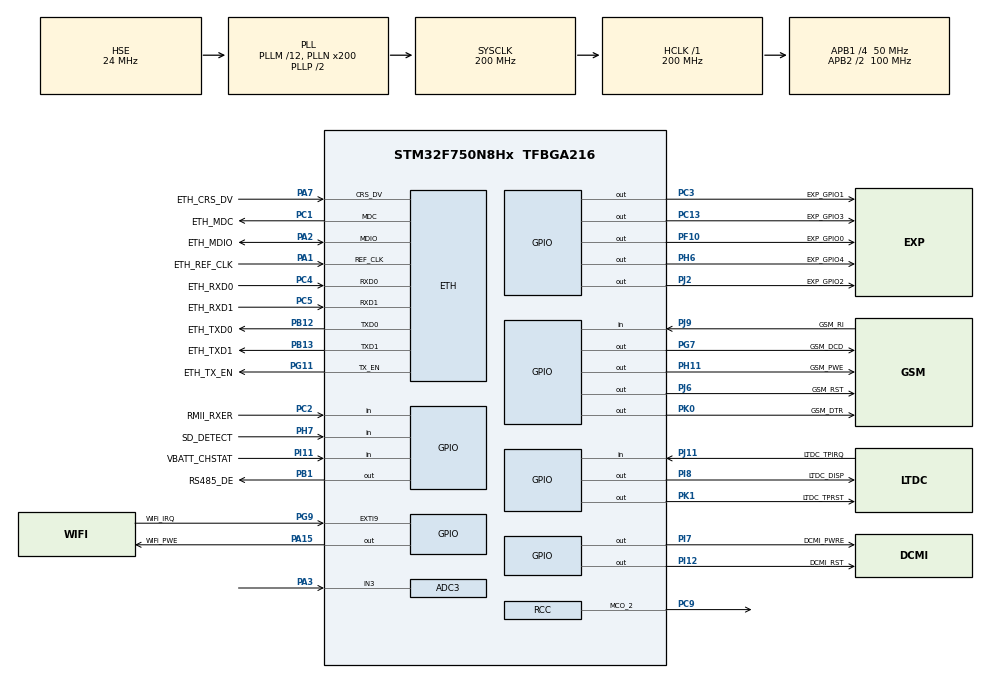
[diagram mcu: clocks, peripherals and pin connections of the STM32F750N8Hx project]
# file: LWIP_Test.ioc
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ADC1.Channel-2\#ChannelRegularConversion=ADC_CHANNEL_3
ADC1.ClockPrescaler=ADC_CLOCK_SYNC_PCLK_DIV6
ADC1.NbrOfConversionFlag=1
ADC1.Rank-2\#ChannelRegularConversion=1
ADC1.SamplingTime-2\#ChannelRegularConversion=ADC_SAMPLETIME_3CYCLES
ADC1.master=1
ADC3.Channel-0\#ChannelRegularConversion=ADC_CHANNEL_3
ADC3.ClockPrescaler=ADC_CLOCK_SYNC_PCLK_DIV6
ADC3.InjNumberOfConversion=0
ADC3.NbrOfConversion=1
ADC3.NbrOfConversionFlag=1
ADC3.Rank-0\#ChannelRegularConversion=1
ADC3.SamplingTime-0\#ChannelRegularConversion=ADC_SAMPLETIME_3CYCLES
ETH.MediaInterface=ETH_MEDIA_INTERFACE_RMII
ETH.PhyAddress=0
FREERTOS.Tasks01=defaultTask,0,128,StartDefaultTask,Default,NULL
LWIP.GATEWAY_ADDRESS=192.168.001.001
LWIP.IP_ADDRESS=192.168.001.050
LWIP.LWIP_DHCP=0
LWIP.NETMASK_ADDRESS=255.255.255.000
LWIP.Version=v2.0.3_Cube
Mcu.Family=STM32F7
Mcu.Name=STM32F750N8Hx
Mcu.Package=TFBGA216
NVIC.ETH_IRQn=true\:5\:0\:false\:false\:true\:true\:false\:true
NVIC.PriorityGroup=NVIC_PRIORITYGROUP_4
NVIC.RCC_IRQn=true\:5\:0\:false\:false\:true\:true\:true\:false
NVIC.TIM1_UP_TIM10_IRQn=true\:0\:0\:false\:false\:true\:false\:false\:true
NVIC.TimeBase=TIM1_UP_TIM10_IRQn
NVIC.TimeBaseIP=TIM1
PA0/WKUP.GPIO_Label=SYS_WAKUP
PA0/WKUP.Mode=SYS_WakeUp0
PA0/WKUP.Signal=SYS_WKUP1
PA1.GPIO_Label=ETH_REF_CLK
PA1.Mode=RMII
PA1.Signal=ETH_REF_CLK
PA10.GPIO_Label=WiFi_RX
PA10.Signal=USART1_RX
PA11.GPIO_Label=WiFi_CTS
PA11.Signal=USART1_CTS
PA12.GPIO_Label=WiFi_RTS
PA12.Signal=USART1_RTS
PA13.GPIO_Label=SWDIO
PA13.Mode=Trace_Asynchronous_SW
PA13.Signal=SYS_JTMS-SWDIO
PA14.GPIO_Label=SWCLK
PA14.Mode=Trace_Asynchronous_SW
PA14.Signal=SYS_JTCK-SWCLK
PA15.GPIO_Label=WiFi_PWE
PA15.Signal=GPIO_Output
PA2.GPIO_Label=ETH_MDIO
PA2.Mode=RMII
PA2.Signal=ETH_MDIO
PA3.Signal=ADCx_IN3
PA4.GPIO_Label=DCMI_HSYNC
PA4.GPIO_Speed=GPIO_SPEED_FREQ_VERY_HIGH
PA4.Signal=DCMI_HSYNC
PA5.GPIO_Label=DCMI_SCL
PA5.Signal=SPI1_SCK
PA6.GPIO_Label=DCMI_PIXCLK
PA6.GPIO_Speed=GPIO_SPEED_FREQ_VERY_HIGH
PA6.Signal=DCMI_PIXCLK
PA7.GPIO_Label=ETH_CRS_DV
PA7.Mode=RMII
PA7.Signal=ETH_CRS_DV
PA8.Signal=I2C3_SCL
PA9.GPIO_Label=WiFi_TX
PA9.Signal=USART1_TX
PB0.GPIO_Label=DCMI_LIGHT
PB0.Signal=TIM8_CH2N
PB1.GPIO_Label=RS485_DE
PB1.Signal=GPIO_Output
PB10.GPIO_Label=RS485_TX
PB10.Signal=USART3_TX
PB11.GPIO_Label=RS485_RX
PB11.Signal=USART3_RX
PB12.GPIO_Label=ETH_TXD0
PB12.Mode=RMII
PB12.Signal=ETH_TXD0
PB13.GPIO_Label=ETH_TXD1
PB13.Mode=RMII
PB13.Signal=ETH_TXD1
PB14.GPIO_Label=USB_DM
PB14.Signal=USB_OTG_HS_DM
PB15.GPIO_Label=USB_DP
PB15.Signal=USB_OTG_HS_DP
PB2.GPIO_Label=QSP_CLK
PB2.Signal=QUADSPI_CLK
PB3.GPIO_Label=SWO
PB3.Mode=Trace_Asynchronous_SW
PB3.Signal=SYS_JTDO-SWO
PB4.GPIO_Label=DCMI_MISO
PB4.Signal=SPI1_MISO
PB5.GPIO_Label=DCMI_MOSI
PB5.Signal=SPI1_MOSI
PB6.GPIO_Label=QSP_NCS
PB6.Signal=QUADSPI_BK1_NCS
PB7.GPIO_Label=DCMI_SDA
PB7.Signal=I2C1_SDA
PB8.GPIO_Label=DCMI_SCL
PB8.Signal=I2C1_SCL
PB9.GPIO_Label=CAN_TX
PB9.Signal=CAN1_TX
PC0.GPIO_Label=FMC_SDNWE
PC0.Signal=FMC_SDNWE
PC1.GPIO_Label=ETH_MDC
PC1.Mode=RMII
PC1.Signal=ETH_MDC
PC10.GPIO_Label=SD_D2
PC10.Signal=SDMMC1_D2
PC11.GPIO_Label=SD_D3
PC11.Signal=SDMMC1_D3
PC12.GPIO_Label=SD_CK
PC12.Signal=SDMMC1_CK
PC13.GPIO_Label=EXP_GPIO3
PC13.Signal=GPIO_Output
PC14/OSC32_IN.GPIO_Label=LS_OSC1
PC14/OSC32_IN.Mode=LSE-External-Oscillator
PC14/OSC32_IN.Signal=RCC_OSC32_IN
PC15/OSC32_OUT.GPIO_Label=LS_OSC2
PC15/OSC32_OUT.Mode=LSE-External-Oscillator
PC15/OSC32_OUT.Signal=RCC_OSC32_OUT
PC2.GPIO_Label=RMII_RXER
PC2.Signal=GPIO_Input
PC3.GPIO_Label=EXP_GPIO1
PC3.Signal=GPIO_Output
PC4.GPIO_Label=ETH_RXD0
PC4.Mode=RMII
PC4.Signal=ETH_RXD0
PC5.GPIO_Label=ETH_RXD1
PC5.Mode=RMII
PC5.Signal=ETH_RXD1
PC6.GPIO_Label=DCMI_D0
PC6.GPIO_Speed=GPIO_SPEED_FREQ_VERY_HIGH
PC6.Signal=DCMI_D0
PC7.GPIO_Label=GSM_RX
PC7.Signal=USART6_RX
PC8.GPIO_Label=SD_D0
PC8.Signal=SDMMC1_D0
PC9.Mode=Clock-out-2
PC9.Signal=RCC_MCO_2
PD0.GPIO_Label=FMC_D2
PD0.Signal=FMC_D2_DA2
PD1.GPIO_Label=FMC_D3
PD1.Signal=FMC_D3_DA3
PD10.GPIO_Label=FMC_D15
PD10.Signal=FMC_D15_DA15
PD11.GPIO_Label=FMC_A16
PD11.Signal=FMC_A16_CLE
PD12.GPIO_Label=FMC_A17
PD12.Signal=FMC_A17_ALE
PD13.GPIO_Label=FMC_A18
PD13.Signal=FMC_A18
PD14.GPIO_Label=FMC_D0
PD14.Signal=FMC_D0_DA0
PD15.GPIO_Label=FMC_D1
PD15.Signal=FMC_D1_DA1
PD2.GPIO_Label=SD_CMD
PD2.Signal=SDMMC1_CMD
PD3.GPIO_Label=WiFi_SCK
PD3.Signal=SPI2_SCK
PD4.GPIO_Label=FMC_NOE
PD4.Signal=FMC_NOE
PD5.GPIO_Label=FMC_NWE
PD5.Signal=FMC_NWE
PD6.GPIO_Label=FMC_NWAIT
PD6.Signal=FMC_NWAIT
PD7.GPIO_Label=FMC_NE
PD7.Signal=FMC_NE1
PD8.GPIO_Label=FMC_D13
PD8.Signal=FMC_D13_DA13
PD9.GPIO_Label=FMC_D14
PD9.Signal=FMC_D14_DA14
PE0.GPIO_Label=FMC_NBL0
PE0.Signal=FMC_NBL0
PE1.GPIO_Label=FMC_NBL1
PE1.Signal=FMC_NBL1
PE10.GPIO_Label=FMC_D7
PE10.Signal=FMC_D7_DA7
PE11.GPIO_Label=FMC_D8
PE11.Signal=FMC_D8_DA8
PE12.GPIO_Label=FMC_D9
PE12.Signal=FMC_D9_DA9
PE13.GPIO_Label=FMC_D10
PE13.Signal=FMC_D10_DA10
PE14.GPIO_Label=FMC_D11
PE14.Signal=FMC_D11_DA11
PE15.GPIO_Label=FMC_D12
PE15.Signal=FMC_D12_DA12
PE2.GPIO_Label=QSP_IO2
PE2.Signal=QUADSPI_BK1_IO2
PE3.GPIO_Label=FMC_A19
PE3.Signal=FMC_A19
PE4.GPIO_Label=FMC_A20
PE4.Signal=FMC_A20
PE5.GPIO_Label=FMC_A21
PE5.Signal=FMC_A21
PE6.GPIO_Label=DCMI_D7
PE6.GPIO_Speed=GPIO_SPEED_FREQ_VERY_HIGH
PE6.Signal=DCMI_D7
PE7.GPIO_Label=FMC_D4
PE7.Signal=FMC_D4_DA4
PE8.GPIO_Label=FMC_D5
PE8.Signal=FMC_D5_DA5
PE9.GPIO_Label=FMC_D6
PE9.Signal=FMC_D6_DA6
PF0.GPIO_Label=FMC_A0
PF0.Signal=FMC_A0
PF1.GPIO_Label=FMC_A1
PF1.Signal=FMC_A1
PF10.GPIO_Label=EXP_GPIO0
PF10.Signal=GPIO_Output
PF11.GPIO_Label=FMC_SDNRAS
PF11.Signal=FMC_SDNRAS
PF12.GPIO_Label=FMC_A6
PF12.Signal=FMC_A6
PF13.GPIO_Label=FMC_A7
PF13.Signal=FMC_A7
PF14.GPIO_Label=FMC_A8
PF14.Signal=FMC_A8
PF15.GPIO_Label=FMC_A9
PF15.Signal=FMC_A9
PF2.GPIO_Label=FMC_A2
PF2.Signal=FMC_A2
PF3.GPIO_Label=FMC_A3
PF3.Signal=FMC_A3
PF4.GPIO_Label=FMC_A4
PF4.Signal=FMC_A4
PF5.GPIO_Label=FMC_A5
PF5.Signal=FMC_A5
PF6.GPIO_Label=QSP_IO3
PF6.Signal=QUADSPI_BK1_IO3
PF7.GPIO_Label=LTDC_BL
PF7.Signal=S_TIM11_CH1
PF8.GPIO_Label=QSP_IO0
PF8.Signal=QUADSPI_BK1_IO0
PF9.GPIO_Label=QSP_IO1
PF9.Signal=QUADSPI_BK1_IO1
PG0.GPIO_Label=FMC_A10
PG0.Signal=FMC_A10
PG1.GPIO_Label=FMC_A11
PG1.Signal=FMC_A11
PG10.GPIO_Label=DCMI_D2
PG10.GPIO_Speed=GPIO_SPEED_FREQ_VERY_HIGH
PG10.Signal=DCMI_D2
PG11.GPIO_Label=ETH_TX_EN
PG11.Mode=RMII
PG11.Signal=ETH_TX_EN
PG12.GPIO_Label=GSM_RTS
PG12.Signal=USART6_RTS
PG13.GPIO_Label=GSM_CTS
PG13.Signal=USART6_CTS
PG14.GPIO_Label=GSM_TX
PG14.Signal=USART6_TX
PG15.GPIO_Label=FMC_SDNCAS
PG15.Signal=FMC_SDNCAS
PG2.GPIO_Label=FMC_A12
PG2.Signal=FMC_A12
PG3.GPIO_Label=FMC_A13
PG3.Signal=FMC_A13
PG4.GPIO_Label=FMC_A14
PG4.Signal=FMC_A14_BA0
PG5.GPIO_Label=FMC_A15
PG5.Signal=FMC_A15_BA1
PG6.GPIO_Label=LTDC_R7
PG6.GPIO_Speed=GPIO_SPEED_FREQ_VERY_HIGH
PG6.Signal=LTDC_R7
PG7.GPIO_Label=GSM_DCD
PG7.Signal=GPIO_Output
PG8.GPIO_Label=FMC_SDCLK
PG8.Signal=FMC_SDCLK
PG9.GPIO_Label=WiFi_IRQ
PG9.Signal=GPXTI9
PH0/OSC_IN.GPIO_Label=HS_OSC1
PH0/OSC_IN.Mode=HSE-External-Oscillator
PH0/OSC_IN.Signal=RCC_OSC_IN
PH1/OSC_OUT.GPIO_Label=HS_OSC2
PH1/OSC_OUT.Mode=HSE-External-Oscillator
PH1/OSC_OUT.Signal=RCC_OSC_OUT
PH10.GPIO_Label=DCMI_D1
PH10.GPIO_Speed=GPIO_SPEED_FREQ_VERY_HIGH
PH10.Signal=DCMI_D1
PH11.GPIO_Label=GSM_PWE
PH11.Signal=GPIO_Output
PH12.GPIO_Label=DCMI_D3
PH12.GPIO_Speed=GPIO_SPEED_FREQ_VERY_HIGH
PH12.Signal=DCMI_D3
PH13.GPIO_Label=LTDC_G2
PH13.GPIO_Speed=GPIO_SPEED_FREQ_VERY_HIGH
PH13.Signal=LTDC_G2
PH14.GPIO_Label=DCMI_D4
PH14.GPIO_Speed=GPIO_SPEED_FREQ_VERY_HIGH
PH14.Signal=DCMI_D4
PH15.GPIO_Label=LTDC_G4
PH15.GPIO_Speed=GPIO_SPEED_FREQ_VERY_HIGH
PH15.Signal=LTDC_G4
PH2.GPIO_Label=FMC_SDCKE0
PH2.Signal=FMC_SDCKE0
PH3.GPIO_Label=FMC_SDNE0
PH3.Signal=FMC_SDNE0
PH4.GPIO_Label=LTDC_SCL
PH4.Signal=I2C2_SCL
PH5.GPIO_Label=LTDC_SDA
PH5.Signal=I2C2_SDA
PH6.GPIO_Label=EXP_GPIO4
PH6.Signal=GPIO_Output
PH7.GPIO_Label=SD_DETECT
PH7.Signal=GPIO_Input
PH8.GPIO_Label=EXP_SDA
PH8.Signal=I2C3_SDA
PH9.GPIO_Label=LTDC_R3
PH9.GPIO_Speed=GPIO_SPEED_FREQ_VERY_HIGH
PH9.Signal=LTDC_R3
PI0.GPIO_Label=LTDC_G5
PI0.GPIO_Speed=GPIO_SPEED_FREQ_VERY_HIGH
PI0.Signal=LTDC_G5
PI1.GPIO_Label=LTDC_G6
PI1.GPIO_Speed=GPIO_SPEED_FREQ_VERY_HIGH
PI1.Signal=LTDC_G6
PI10.GPIO_Label=LTDC_HSYNC
PI10.GPIO_Speed=GPIO_SPEED_FREQ_VERY_HIGH
PI10.Signal=LTDC_HSYNC
PI11.GPIO_Label=VBATT_CHSTAT
PI11.Signal=GPIO_Input
PI12.GPIO_Label=DCMI_RST
PI12.Signal=GPIO_Output
PI13.GPIO_Label=LTDC_VSYNC
PI13.GPIO_Speed=GPIO_SPEED_FREQ_VERY_HIGH
PI13.Signal=LTDC_VSYNC
PI14.GPIO_Label=LTDC_CLK
PI14.GPIO_Speed=GPIO_SPEED_FREQ_VERY_HIGH
PI14.Signal=LTDC_CLK
PI15.GPIO_Label=LTDC_R0
PI15.GPIO_Speed=GPIO_SPEED_FREQ_VERY_HIGH
PI15.Signal=LTDC_R0
PI2.GPIO_Label=WiFi_MISO
PI2.Signal=SPI2_MISO
PI3.GPIO_Label=WiFi_MOSI
PI3.Signal=SPI2_MOSI
PI4.GPIO_Label=DCMI_D5
PI4.GPIO_Speed=GPIO_SPEED_FREQ_VERY_HIGH
PI4.Signal=DCMI_D5
PI5.GPIO_Label=DCMI_VSYNC
PI5.GPIO_Speed=GPIO_SPEED_FREQ_VERY_HIGH
PI5.Signal=DCMI_VSYNC
PI6.GPIO_Label=DCMI_D6
PI6.GPIO_Speed=GPIO_SPEED_FREQ_VERY_HIGH
PI6.Signal=DCMI_D6
PI7.GPIO_Label=DCMI_PWRE
PI7.Signal=GPIO_Output
PI8.GPIO_Label=LTDC_DISP
PI8.Signal=GPIO_Output
PI9.GPIO_Label=CAN_RX
PI9.Signal=CAN1_RX
PJ0.GPIO_Label=LTDC_R1
PJ0.GPIO_Speed=GPIO_SPEED_FREQ_VERY_HIGH
PJ0.Signal=LTDC_R1
PJ1.GPIO_Label=LTDC_R2
PJ1.GPIO_Speed=GPIO_SPEED_FREQ_VERY_HIGH
PJ1.Signal=LTDC_R2
PJ10.GPIO_Label=LTDC_G3
PJ10.GPIO_Speed=GPIO_SPEED_FREQ_VERY_HIGH
PJ10.Signal=LTDC_G3
PJ11.GPIO_Label=LTDC_TPIRQ
PJ11.Signal=GPIO_Input
PJ12.GPIO_Label=LTDC_B0
PJ12.GPIO_Speed=GPIO_SPEED_FREQ_VERY_HIGH
PJ12.Signal=LTDC_B0
PJ13.GPIO_Label=LTDC_B1
PJ13.GPIO_Speed=GPIO_SPEED_FREQ_VERY_HIGH
PJ13.Signal=LTDC_B1
PJ14.GPIO_Label=LTDC_B2
PJ14.GPIO_Speed=GPIO_SPEED_FREQ_VERY_HIGH
PJ14.Signal=LTDC_B2
PJ15.GPIO_Label=LTDC_B3
PJ15.GPIO_Speed=GPIO_SPEED_FREQ_VERY_HIGH
PJ15.Signal=LTDC_B3
PJ2.GPIO_Label=EXP_GPIO2
PJ2.Signal=GPIO_Output
PJ3.GPIO_Label=LTDC_R4
PJ3.GPIO_Speed=GPIO_SPEED_FREQ_VERY_HIGH
PJ3.Signal=LTDC_R4
PJ4.GPIO_Label=LTDC_R5
PJ4.GPIO_Speed=GPIO_SPEED_FREQ_VERY_HIGH
PJ4.Signal=LTDC_R5
PJ5.GPIO_Label=LTDC_R6
PJ5.GPIO_Speed=GPIO_SPEED_FREQ_VERY_HIGH
PJ5.Signal=LTDC_R6
PJ6.GPIO_Label=GSM_RST
PJ6.Signal=GPIO_Output
PJ7.GPIO_Label=LTDC_G0
PJ7.GPIO_Speed=GPIO_SPEED_FREQ_VERY_HIGH
PJ7.Signal=LTDC_G0
PJ8.GPIO_Label=LTDC_G1
PJ8.GPIO_Speed=GPIO_SPEED_FREQ_VERY_HIGH
PJ8.Signal=LTDC_G1
PJ9.GPIO_Label=GSM_RI
PJ9.Signal=GPIO_Input
PK0.GPIO_Label=GSM_DTR
PK0.Signal=GPIO_Output
PK1.GPIO_Label=LTDC_TPRST
PK1.Signal=GPIO_Output
PK2.GPIO_Label=LTDC_G7
PK2.GPIO_Speed=GPIO_SPEED_FREQ_VERY_HIGH
PK2.Signal=LTDC_G7
PK3.GPIO_Label=LTDC_B4
PK3.GPIO_Speed=GPIO_SPEED_FREQ_VERY_HIGH
PK3.Signal=LTDC_B4
PK4.GPIO_Label=LTDC_B5
PK4.GPIO_Speed=GPIO_SPEED_FREQ_VERY_HIGH
PK4.Signal=LTDC_B5
PK5.GPIO_Label=LTDC_B6
PK5.GPIO_Speed=GPIO_SPEED_FREQ_VERY_HIGH
PK5.Signal=LTDC_B6
PK6.GPIO_Label=LTDC_B7
PK6.GPIO_Speed=GPIO_SPEED_FREQ_VERY_HIGH
PK6.Signal=LTDC_B7
PK7.GPIO_Label=LTDC_DE
PK7.GPIO_Speed=GPIO_SPEED_FREQ_VERY_HIGH
PK7.Signal=LTDC_DE
ProjectManager.HeapSize=0x1000
ProjectManager.StackSize=0x1000
ProjectManager.TargetToolchain=MDK-ARM V5
RCC.AHBFreq_Value=200000000
RCC.APB1CLKDivider=RCC_HCLK_DIV4
RCC.APB1Freq_Value=50000000
RCC.APB1TimFreq_Value=100000000
RCC.APB2CLKDivider=RCC_HCLK_DIV2
RCC.APB2Freq_Value=100000000
RCC.APB2TimFreq_Value=200000000
RCC.CortexFreq_Value=200000000
RCC.HCLKFreq_Value=200000000
RCC.HSE_VALUE=24000000
RCC.HSI_VALUE=16000000
RCC.PLLI2SN=50
RCC.PLLM=12
RCC.PLLN=200
RCC.PLLQ=8
RCC.PLLSAIN=200
RCC.PLLSAIP=RCC_PLLSAIP_DIV8
RCC.PLLSAIR=3
RCC.PLLSAIRDiv=RCC_PLLSAIDIVR_4
RCC.PLLSourceVirtual=RCC_PLLSOURCE_HSE
RCC.RCC_MCO1Source=RCC_MCO1SOURCE_HSE
RCC.RCC_MCO2Source=RCC_MCO2SOURCE_PLLI2SCLK
RCC.RCC_MCODiv2=RCC_MCODIV_2
RCC.RCC_RTC_Clock_Source_FROM_HSE=RCC_RTCCLKSOURCE_HSE_DIV30
RCC.RTCClockSelection=RCC_RTCCLKSOURCE_LSE
RCC.SDMMCClockSelection=RCC_SDMMC1CLKSOURCE_CLK48
RCC.SYSCLKFreq_VALUE=200000000
RCC.SYSCLKSource=RCC_SYSCLKSOURCE_PLLCLK
RCC.USBFreq_Value=50000000
RCC.VCOOutputFreq_Value=400000000
SH.ADCx_IN3.0=ADC3_IN3,IN3
SH.ADCx_IN3.1=ADC1_IN3,IN3
SH.FMC_A0.0=FMC_A0
SH.FMC_A1.0=FMC_A1
SH.FMC_A10.0=FMC_A10
SH.FMC_A11.0=FMC_A11
SH.FMC_A12.0=FMC_A12
SH.FMC_A13.0=FMC_A13
SH.FMC_A14_BA0.0=FMC_BA0
SH.FMC_A14_BA0.1=FMC_A14
SH.FMC_A15_BA1.0=FMC_BA1
SH.FMC_A15_BA1.1=FMC_A15
SH.FMC_A16_CLE.0=FMC_A16
SH.FMC_A17_ALE.0=FMC_A17
SH.FMC_A18.0=FMC_A18
SH.FMC_A19.0=FMC_A19
SH.FMC_A2.0=FMC_A2
SH.FMC_A20.0=FMC_A20
SH.FMC_A21.0=FMC_A21
SH.FMC_A3.0=FMC_A3
SH.FMC_A4.0=FMC_A4
SH.FMC_A5.0=FMC_A5
SH.FMC_A6.0=FMC_A6
SH.FMC_A7.0=FMC_A7
SH.FMC_A8.0=FMC_A8
SH.FMC_A9.0=FMC_A9
SH.FMC_D0_DA0.0=FMC_D0
SH.FMC_D10_DA10.0=FMC_D10
SH.FMC_D11_DA11.0=FMC_D11
SH.FMC_D12_DA12.0=FMC_D12
SH.FMC_D13_DA13.0=FMC_D13
SH.FMC_D14_DA14.0=FMC_D14
SH.FMC_D15_DA15.0=FMC_D15
SH.FMC_D1_DA1.0=FMC_D1
SH.FMC_D2_DA2.0=FMC_D2
SH.FMC_D3_DA3.0=FMC_D3
SH.FMC_D4_DA4.0=FMC_D4
SH.FMC_D5_DA5.0=FMC_D5
SH.FMC_D6_DA6.0=FMC_D6
SH.FMC_D7_DA7.0=FMC_D7
SH.FMC_D8_DA8.0=FMC_D8
SH.FMC_D9_DA9.0=FMC_D9
SH.FMC_NBL0.0=FMC_NBL0
SH.FMC_NBL1.0=FMC_NBL1
SH.FMC_NOE.0=FMC_NOE
SH.FMC_NWAIT.0=FMC_NWAIT
SH.FMC_NWE.0=FMC_NWE
SH.FMC_SDCLK.0=FMC_SDCLK
SH.FMC_SDNCAS.0=FMC_SDNCAS
SH.FMC_SDNRAS.0=FMC_SDNRAS
SH.FMC_SDNWE.0=FMC_SDNWE
SH.S_TIM11_CH1.0=TIM11_CH1
VP_FREERTOS_VS_CMSIS_V1.Mode=CMSIS_V1
VP_LWIP_VS_Enabled.Mode=Enabled
VP_SYS_VS_tim1.Mode=TIM1
board=custom

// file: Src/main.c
/* USER CODE BEGIN Header */
/**
  ******************************************************************************
  * @file           : main.c
  * @brief          : Main program body
  ******************************************************************************
  * @attention
  *
  * <h2><center>&copy; Copyright (c) 2020 STMicroelectronics.
  * All rights reserved.</center></h2>
  *
  * This software component is licensed by ST under Ultimate Liberty license
  * SLA0044, the "License"; You may not use this file except in compliance with
  * the License. You may obtain a copy of the License at:
  *                             www.st.com/SLA0044
  *
  ******************************************************************************
  */
/* USER CODE END Header */

#include "main.h"
#include "cmsis_os.h"
#include "lwip.h"

/* USER CODE BEGIN Includes */
#include "httpserver-netconn.h"
/* USER CODE END Includes */

ADC_HandleTypeDef hadc1;
ADC_HandleTypeDef hadc3;

osThreadId defaultTaskHandle;

void SystemClock_Config(void);
static void MX_GPIO_Init(void);
static void MX_ADC3_Init(void);
static void MX_ADC1_Init(void);
void StartDefaultTask(void const * argument);

int main(void)
{

  /* MCU Configuration--------------------------------------------------------*/

  /* Reset of all peripherals, Initializes the Flash interface and the Systick. */
  HAL_Init();

  /* Configure the system clock */
  SystemClock_Config();

  /* Initialize all configured peripherals */
  MX_GPIO_Init();
  MX_ADC3_Init();
  MX_ADC1_Init();

  /* Create the thread(s) */
  /* definition and creation of defaultTask */
  osThreadDef(defaultTask, StartDefaultTask, osPriorityNormal, 0, 128);
  defaultTaskHandle = osThreadCreate(osThread(defaultTask), NULL);

  /* Start scheduler */
  osKernelStart();

  /* We should never get here as control is now taken by the scheduler */

  /* Infinite loop */
  while (1)
  {

  }
}

void SystemClock_Config(void)
{
  RCC_OscInitTypeDef RCC_OscInitStruct = {0};
  RCC_ClkInitTypeDef RCC_ClkInitStruct = {0};
  RCC_PeriphCLKInitTypeDef PeriphClkInitStruct = {0};

  /** Configure LSE Drive Capability
  */
  HAL_PWR_EnableBkUpAccess();
  /** Configure the main internal regulator output voltage
  */
  __HAL_RCC_PWR_CLK_ENABLE();
  __HAL_PWR_VOLTAGESCALING_CONFIG(PWR_REGULATOR_VOLTAGE_SCALE1);
  /** Initializes the CPU, AHB and APB busses clocks
  */
  RCC_OscInitStruct.OscillatorType = RCC_OSCILLATORTYPE_HSE;
  RCC_OscInitStruct.HSEState = RCC_HSE_ON;
  RCC_OscInitStruct.PLL.PLLState = RCC_PLL_ON;
  RCC_OscInitStruct.PLL.PLLSource = RCC_PLLSOURCE_HSE;
  RCC_OscInitStruct.PLL.PLLM = 12;
  RCC_OscInitStruct.PLL.PLLN = 200;
  RCC_OscInitStruct.PLL.PLLP = RCC_PLLP_DIV2;
  RCC_OscInitStruct.PLL.PLLQ = 8;
  if (HAL_RCC_OscConfig(&RCC_OscInitStruct) != HAL_OK)
  {
    Error_Handler();
  }
  /** Activate the Over-Drive mode
  */
  if (HAL_PWREx_EnableOverDrive() != HAL_OK)
  {
    Error_Handler();
  }
  /** Initializes the CPU, AHB and APB busses clocks
  */
  RCC_ClkInitStruct.ClockType = RCC_CLOCKTYPE_HCLK|RCC_CLOCKTYPE_SYSCLK
                              |RCC_CLOCKTYPE_PCLK1|RCC_CLOCKTYPE_PCLK2;
  RCC_ClkInitStruct.SYSCLKSource = RCC_SYSCLKSOURCE_PLLCLK;
  RCC_ClkInitStruct.AHBCLKDivider = RCC_SYSCLK_DIV1;
  RCC_ClkInitStruct.APB1CLKDivider = RCC_HCLK_DIV4;
  RCC_ClkInitStruct.APB2CLKDivider = RCC_HCLK_DIV2;

  if (HAL_RCC_ClockConfig(&RCC_ClkInitStruct, FLASH_LATENCY_6) != HAL_OK)
  {
    Error_Handler();
  }
  PeriphClkInitStruct.PeriphClockSelection = RCC_PERIPHCLK_PLLI2S;
  PeriphClkInitStruct.PLLI2S.PLLI2SN = 50;
  PeriphClkInitStruct.PLLI2S.PLLI2SP = RCC_PLLP_DIV2;
  PeriphClkInitStruct.PLLI2S.PLLI2SR = 2;
  PeriphClkInitStruct.PLLI2S.PLLI2SQ = 2;
  PeriphClkInitStruct.PLLI2SDivQ = 1;
  if (HAL_RCCEx_PeriphCLKConfig(&PeriphClkInitStruct) != HAL_OK)
  {
    Error_Handler();
  }
  HAL_RCC_MCOConfig(RCC_MCO2, RCC_MCO2SOURCE_PLLI2SCLK, RCC_MCODIV_2);
}

static void MX_ADC1_Init(void)
{

  ADC_ChannelConfTypeDef sConfig = {0};

  /** Configure the global features of the ADC (Clock, Resolution, Data Alignment and number of conversion)
  */
  hadc1.Instance = ADC1;
  hadc1.Init.ClockPrescaler = ADC_CLOCK_SYNC_PCLK_DIV6;
  hadc1.Init.Resolution = ADC_RESOLUTION_12B;
  hadc1.Init.ScanConvMode = ADC_SCAN_DISABLE;
  hadc1.Init.ContinuousConvMode = DISABLE;
  hadc1.Init.DiscontinuousConvMode = DISABLE;
  hadc1.Init.ExternalTrigConvEdge = ADC_EXTERNALTRIGCONVEDGE_NONE;
  hadc1.Init.ExternalTrigConv = ADC_SOFTWARE_START;
  hadc1.Init.DataAlign = ADC_DATAALIGN_RIGHT;
  hadc1.Init.NbrOfConversion = 1;
  hadc1.Init.DMAContinuousRequests = DISABLE;
  hadc1.Init.EOCSelection = ADC_EOC_SINGLE_CONV;
  if (HAL_ADC_Init(&hadc1) != HAL_OK)
  {
    Error_Handler();
  }
  /** Configure for the selected ADC regular channel its corresponding rank in the sequencer and its sample time.
  */
  sConfig.Channel = ADC_CHANNEL_3;
  sConfig.Rank = ADC_REGULAR_RANK_1;
  sConfig.SamplingTime = ADC_SAMPLETIME_3CYCLES;
  if (HAL_ADC_ConfigChannel(&hadc1, &sConfig) != HAL_OK)
  {
    Error_Handler();
  }

}

static void MX_ADC3_Init(void)
{

  ADC_ChannelConfTypeDef sConfig = {0};

  /** Configure the global features of the ADC (Clock, Resolution, Data Alignment and number of conversion)
  */
  hadc3.Instance = ADC3;
  hadc3.Init.ClockPrescaler = ADC_CLOCK_SYNC_PCLK_DIV6;
  hadc3.Init.Resolution = ADC_RESOLUTION_12B;
  hadc3.Init.ScanConvMode = ADC_SCAN_DISABLE;
  hadc3.Init.ContinuousConvMode = DISABLE;
  hadc3.Init.DiscontinuousConvMode = DISABLE;
  hadc3.Init.ExternalTrigConvEdge = ADC_EXTERNALTRIGCONVEDGE_NONE;
  hadc3.Init.ExternalTrigConv = ADC_SOFTWARE_START;
  hadc3.Init.DataAlign = ADC_DATAALIGN_RIGHT;
  hadc3.Init.NbrOfConversion = 1;
  hadc3.Init.DMAContinuousRequests = DISABLE;
  hadc3.Init.EOCSelection = ADC_EOC_SINGLE_CONV;
  if (HAL_ADC_Init(&hadc3) != HAL_OK)
  {
    Error_Handler();
  }
  /** Configure for the selected ADC regular channel its corresponding rank in the sequencer and its sample time.
  */
  sConfig.Channel = ADC_CHANNEL_3;
  sConfig.Rank = ADC_REGULAR_RANK_1;
  sConfig.SamplingTime = ADC_SAMPLETIME_3CYCLES;
  if (HAL_ADC_ConfigChannel(&hadc3, &sConfig) != HAL_OK)
  {
    Error_Handler();
  }

}

static void MX_GPIO_Init(void)
{
  GPIO_InitTypeDef GPIO_InitStruct = {0};

  /* GPIO Ports Clock Enable */
  __HAL_RCC_GPIOE_CLK_ENABLE();
  __HAL_RCC_GPIOG_CLK_ENABLE();
  __HAL_RCC_GPIOB_CLK_ENABLE();
  __HAL_RCC_GPIOD_CLK_ENABLE();
  __HAL_RCC_GPIOC_CLK_ENABLE();
  __HAL_RCC_GPIOA_CLK_ENABLE();
  __HAL_RCC_GPIOJ_CLK_ENABLE();
  __HAL_RCC_GPIOI_CLK_ENABLE();
  __HAL_RCC_GPIOK_CLK_ENABLE();
  __HAL_RCC_GPIOF_CLK_ENABLE();
  __HAL_RCC_GPIOH_CLK_ENABLE();

  /*Configure GPIO pin Output Level */
  HAL_GPIO_WritePin(WiFi_PWE_GPIO_Port, WiFi_PWE_Pin, GPIO_PIN_RESET);

  /*Configure GPIO pin Output Level */
  HAL_GPIO_WritePin(GPIOI, LTDC_DISP_Pin|DCMI_PWRE_Pin|DCMI_RST_Pin, GPIO_PIN_RESET);

  /*Configure GPIO pin Output Level */
  HAL_GPIO_WritePin(GPIOC, EXP_GPIO3_Pin|EXP_GPIO1_Pin, GPIO_PIN_RESET);

  /*Configure GPIO pin Output Level */
  HAL_GPIO_WritePin(GPIOK, LTDC_TPRST_Pin|GSM_DTR_Pin, GPIO_PIN_RESET);

  /*Configure GPIO pin Output Level */
  HAL_GPIO_WritePin(GSM_DCD_GPIO_Port, GSM_DCD_Pin, GPIO_PIN_RESET);

  /*Configure GPIO pin Output Level */
  HAL_GPIO_WritePin(GPIOJ, GSM_RST_Pin|EXP_GPIO2_Pin, GPIO_PIN_RESET);

  /*Configure GPIO pin Output Level */
  HAL_GPIO_WritePin(EXP_GPIO0_GPIO_Port, EXP_GPIO0_Pin, GPIO_PIN_RESET);

  /*Configure GPIO pin Output Level */
  HAL_GPIO_WritePin(GPIOH, GSM_PWE_Pin|EXP_GPIO4_Pin, GPIO_PIN_RESET);

  /*Configure GPIO pin Output Level */
  HAL_GPIO_WritePin(RS485_DE_GPIO_Port, RS485_DE_Pin, GPIO_PIN_RESET);

  /*Configure GPIO pins : FMC_A20_Pin FMC_A19_Pin FMC_NBL1_Pin FMC_NBL0_Pin
                           FMC_A21_Pin FMC_D5_Pin FMC_D6_Pin FMC_D8_Pin
                           FMC_D11_Pin FMC_D4_Pin FMC_D7_Pin FMC_D9_Pin
                           FMC_D12_Pin FMC_D10_Pin */
  GPIO_InitStruct.Pin = FMC_A20_Pin|FMC_A19_Pin|FMC_NBL1_Pin|FMC_NBL0_Pin
                          |FMC_A21_Pin|FMC_D5_Pin|FMC_D6_Pin|FMC_D8_Pin
                          |FMC_D11_Pin|FMC_D4_Pin|FMC_D7_Pin|FMC_D9_Pin
                          |FMC_D12_Pin|FMC_D10_Pin;
  GPIO_InitStruct.Mode = GPIO_MODE_AF_PP;
  GPIO_InitStruct.Pull = GPIO_NOPULL;
  GPIO_InitStruct.Speed = GPIO_SPEED_FREQ_VERY_HIGH;
  GPIO_InitStruct.Alternate = GPIO_AF12_FMC;
  HAL_GPIO_Init(GPIOE, &GPIO_InitStruct);

  /*Configure GPIO pin : QSP_IO2_Pin */
  GPIO_InitStruct.Pin = QSP_IO2_Pin;
  GPIO_InitStruct.Mode = GPIO_MODE_AF_PP;
  GPIO_InitStruct.Pull = GPIO_NOPULL;
  GPIO_InitStruct.Speed = GPIO_SPEED_FREQ_VERY_HIGH;
  GPIO_InitStruct.Alternate = GPIO_AF9_QUADSPI;
  HAL_GPIO_Init(QSP_IO2_GPIO_Port, &GPIO_InitStruct);

  /*Configure GPIO pins : GSM_TX_Pin GSM_CTS_Pin GSM_RTS_Pin */
  GPIO_InitStruct.Pin = GSM_TX_Pin|GSM_CTS_Pin|GSM_RTS_Pin;
  GPIO_InitStruct.Mode = GPIO_MODE_AF_PP;
  GPIO_InitStruct.Pull = GPIO_NOPULL;
  GPIO_InitStruct.Speed = GPIO_SPEED_FREQ_VERY_HIGH;
  GPIO_InitStruct.Alternate = GPIO_AF8_USART6;
  HAL_GPIO_Init(GPIOG, &GPIO_InitStruct);

  /*Configure GPIO pins : DCMI_SCL_Pin DCMI_SDA_Pin */
  GPIO_InitStruct.Pin = DCMI_SCL_Pin|DCMI_SDA_Pin;
  GPIO_InitStruct.Mode = GPIO_MODE_AF_OD;
  GPIO_InitStruct.Pull = GPIO_PULLUP;
  GPIO_InitStruct.Speed = GPIO_SPEED_FREQ_VERY_HIGH;
  GPIO_InitStruct.Alternate = GPIO_AF4_I2C1;
  HAL_GPIO_Init(GPIOB, &GPIO_InitStruct);

  /*Configure GPIO pins : DCMI_MOSI_Pin DCMI_MISO_Pin */
  GPIO_InitStruct.Pin = DCMI_MOSI_Pin|DCMI_MISO_Pin;
  GPIO_InitStruct.Mode = GPIO_MODE_AF_PP;
  GPIO_InitStruct.Pull = GPIO_NOPULL;
  GPIO_InitStruct.Speed = GPIO_SPEED_FREQ_VERY_HIGH;
  GPIO_InitStruct.Alternate = GPIO_AF5_SPI1;
  HAL_GPIO_Init(GPIOB, &GPIO_InitStruct);

  /*Configure GPIO pins : FMC_NE_Pin FMC_NWAIT_Pin FMC_D2_Pin FMC_NWE_Pin
                           FMC_D3_Pin FMC_NOE_Pin FMC_D1_Pin FMC_D15_Pin
                           FMC_D0_Pin FMC_D14_Pin FMC_D13_Pin FMC_A17_Pin
                           FMC_A18_Pin FMC_A16_Pin */
  GPIO_InitStruct.Pin = FMC_NE_Pin|FMC_NWAIT_Pin|FMC_D2_Pin|FMC_NWE_Pin
                          |FMC_D3_Pin|FMC_NOE_Pin|FMC_D1_Pin|FMC_D15_Pin
                          |FMC_D0_Pin|FMC_D14_Pin|FMC_D13_Pin|FMC_A17_Pin
                          |FMC_A18_Pin|FMC_A16_Pin;
  GPIO_InitStruct.Mode = GPIO_MODE_AF_PP;
  GPIO_InitStruct.Pull = GPIO_NOPULL;
  GPIO_InitStruct.Speed = GPIO_SPEED_FREQ_VERY_HIGH;
  GPIO_InitStruct.Alternate = GPIO_AF12_FMC;
  HAL_GPIO_Init(GPIOD, &GPIO_InitStruct);

  /*Configure GPIO pins : SD_CK_Pin SD_D3_Pin SD_D2_Pin SD_D0_Pin */
  GPIO_InitStruct.Pin = SD_CK_Pin|SD_D3_Pin|SD_D2_Pin|SD_D0_Pin;
  GPIO_InitStruct.Mode = GPIO_MODE_AF_PP;
  GPIO_InitStruct.Pull = GPIO_NOPULL;
  GPIO_InitStruct.Speed = GPIO_SPEED_FREQ_VERY_HIGH;
  GPIO_InitStruct.Alternate = GPIO_AF12_SDMMC1;
  HAL_GPIO_Init(GPIOC, &GPIO_InitStruct);

  /*Configure GPIO pin : WiFi_PWE_Pin */
  GPIO_InitStruct.Pin = WiFi_PWE_Pin;
  GPIO_InitStruct.Mode = GPIO_MODE_OUTPUT_PP;
  GPIO_InitStruct.Pull = GPIO_NOPULL;
  GPIO_InitStruct.Speed = GPIO_SPEED_FREQ_LOW;
  HAL_GPIO_Init(WiFi_PWE_GPIO_Port, &GPIO_InitStruct);

  /*Configure GPIO pin : DCMI_D7_Pin */
  GPIO_InitStruct.Pin = DCMI_D7_Pin;
  GPIO_InitStruct.Mode = GPIO_MODE_AF_PP;
  GPIO_InitStruct.Pull = GPIO_NOPULL;
  GPIO_InitStruct.Speed = GPIO_SPEED_FREQ_VERY_HIGH;
  GPIO_InitStruct.Alternate = GPIO_AF13_DCMI;
  HAL_GPIO_Init(DCMI_D7_GPIO_Port, &GPIO_InitStruct);

  /*Configure GPIO pin : CAN_TX_Pin */
  GPIO_InitStruct.Pin = CAN_TX_Pin;
  GPIO_InitStruct.Mode = GPIO_MODE_AF_PP;
  GPIO_InitStruct.Pull = GPIO_NOPULL;
  GPIO_InitStruct.Speed = GPIO_SPEED_FREQ_VERY_HIGH;
  GPIO_InitStruct.Alternate = GPIO_AF9_CAN1;
  HAL_GPIO_Init(CAN_TX_GPIO_Port, &GPIO_InitStruct);

  /*Configure GPIO pin : QSP_NCS_Pin */
  GPIO_InitStruct.Pin = QSP_NCS_Pin;
  GPIO_InitStruct.Mode = GPIO_MODE_AF_PP;
  GPIO_InitStruct.Pull = GPIO_NOPULL;
  GPIO_InitStruct.Speed = GPIO_SPEED_FREQ_VERY_HIGH;
  GPIO_InitStruct.Alternate = GPIO_AF10_QUADSPI;
  HAL_GPIO_Init(QSP_NCS_GPIO_Port, &GPIO_InitStruct);

  /*Configure GPIO pins : FMC_SDNCAS_Pin FMC_SDCLK_Pin FMC_A11_Pin FMC_A13_Pin
                           FMC_A12_Pin FMC_A10_Pin FMC_A15_Pin FMC_A14_Pin */
  GPIO_InitStruct.Pin = FMC_SDNCAS_Pin|FMC_SDCLK_Pin|FMC_A11_Pin|FMC_A13_Pin
                          |FMC_A12_Pin|FMC_A10_Pin|FMC_A15_Pin|FMC_A14_Pin;
  GPIO_InitStruct.Mode = GPIO_MODE_AF_PP;
  GPIO_InitStruct.Pull = GPIO_NOPULL;
  GPIO_InitStruct.Speed = GPIO_SPEED_FREQ_VERY_HIGH;
  GPIO_InitStruct.Alternate = GPIO_AF12_FMC;
  HAL_GPIO_Init(GPIOG, &GPIO_InitStruct);

  /*Configure GPIO pins : LTDC_B1_Pin LTDC_B0_Pin LTDC_B2_Pin LTDC_B3_Pin
                           LTDC_G1_Pin LTDC_G3_Pin LTDC_G0_Pin LTDC_R5_Pin
                           LTDC_R6_Pin LTDC_R4_Pin LTDC_R1_Pin LTDC_R2_Pin */
  GPIO_InitStruct.Pin = LTDC_B1_Pin|LTDC_B0_Pin|LTDC_B2_Pin|LTDC_B3_Pin
                          |LTDC_G1_Pin|LTDC_G3_Pin|LTDC_G0_Pin|LTDC_R5_Pin
                          |LTDC_R6_Pin|LTDC_R4_Pin|LTDC_R1_Pin|LTDC_R2_Pin;
  GPIO_InitStruct.Mode = GPIO_MODE_AF_PP;
  GPIO_InitStruct.Pull = GPIO_NOPULL;
  GPIO_InitStruct.Speed = GPIO_SPEED_FREQ_VERY_HIGH;
  GPIO_InitStruct.Alternate = GPIO_AF14_LTDC;
  HAL_GPIO_Init(GPIOJ, &GPIO_InitStruct);

  /*Configure GPIO pins : WiFi_RTS_Pin WiFi_CTS_Pin WiFi_RX_Pin WiFi_TX_Pin */
  GPIO_InitStruct.Pin = WiFi_RTS_Pin|WiFi_CTS_Pin|WiFi_RX_Pin|WiFi_TX_Pin;
  GPIO_InitStruct.Mode = GPIO_MODE_AF_PP;
  GPIO_InitStruct.Pull = GPIO_NOPULL;
  GPIO_InitStruct.Speed = GPIO_SPEED_FREQ_VERY_HIGH;
  GPIO_InitStruct.Alternate = GPIO_AF7_USART1;
  HAL_GPIO_Init(GPIOA, &GPIO_InitStruct);

  /*Configure GPIO pins : LTDC_DISP_Pin DCMI_PWRE_Pin DCMI_RST_Pin */
  GPIO_InitStruct.Pin = LTDC_DISP_Pin|DCMI_PWRE_Pin|DCMI_RST_Pin;
  GPIO_InitStruct.Mode = GPIO_MODE_OUTPUT_PP;
  GPIO_InitStruct.Pull = GPIO_NOPULL;
  GPIO_InitStruct.Speed = GPIO_SPEED_FREQ_LOW;
  HAL_GPIO_Init(GPIOI, &GPIO_InitStruct);

  /*Configure GPIO pins : DCMI_D5_Pin DCMI_VSYNC_Pin DCMI_D6_Pin */
  GPIO_InitStruct.Pin = DCMI_D5_Pin|DCMI_VSYNC_Pin|DCMI_D6_Pin;
  GPIO_InitStruct.Mode = GPIO_MODE_AF_PP;
  GPIO_InitStruct.Pull = GPIO_NOPULL;
  GPIO_InitStruct.Speed = GPIO_SPEED_FREQ_VERY_HIGH;
  GPIO_InitStruct.Alternate = GPIO_AF13_DCMI;
  HAL_GPIO_Init(GPIOI, &GPIO_InitStruct);

  /*Configure GPIO pins : LTDC_DE_Pin LTDC_B7_Pin LTDC_B6_Pin LTDC_B5_Pin
                           LTDC_B4_Pin LTDC_G7_Pin */
  GPIO_InitStruct.Pin = LTDC_DE_Pin|LTDC_B7_Pin|LTDC_B6_Pin|LTDC_B5_Pin
                          |LTDC_B4_Pin|LTDC_G7_Pin;
  GPIO_InitStruct.Mode = GPIO_MODE_AF_PP;
  GPIO_InitStruct.Pull = GPIO_NOPULL;
  GPIO_InitStruct.Speed = GPIO_SPEED_FREQ_VERY_HIGH;
  GPIO_InitStruct.Alternate = GPIO_AF14_LTDC;
  HAL_GPIO_Init(GPIOK, &GPIO_InitStruct);

  /*Configure GPIO pin : DCMI_D2_Pin */
  GPIO_InitStruct.Pin = DCMI_D2_Pin;
  GPIO_InitStruct.Mode = GPIO_MODE_AF_PP;
  GPIO_InitStruct.Pull = GPIO_NOPULL;
  GPIO_InitStruct.Speed = GPIO_SPEED_FREQ_VERY_HIGH;
  GPIO_InitStruct.Alternate = GPIO_AF13_DCMI;
  HAL_GPIO_Init(DCMI_D2_GPIO_Port, &GPIO_InitStruct);

  /*Configure GPIO pin : WiFi_SCK_Pin */
  GPIO_InitStruct.Pin = WiFi_SCK_Pin;
  GPIO_InitStruct.Mode = GPIO_MODE_AF_PP;
  GPIO_InitStruct.Pull = GPIO_NOPULL;
  GPIO_InitStruct.Speed = GPIO_SPEED_FREQ_VERY_HIGH;
  GPIO_InitStruct.Alternate = GPIO_AF5_SPI2;
  HAL_GPIO_Init(WiFi_SCK_GPIO_Port, &GPIO_InitStruct);

  /*Configure GPIO pins : WiFi_MOSI_Pin WiFi_MISO_Pin */
  GPIO_InitStruct.Pin = WiFi_MOSI_Pin|WiFi_MISO_Pin;
  GPIO_InitStruct.Mode = GPIO_MODE_AF_PP;
  GPIO_InitStruct.Pull = GPIO_NOPULL;
  GPIO_InitStruct.Speed = GPIO_SPEED_FREQ_VERY_HIGH;
  GPIO_InitStruct.Alternate = GPIO_AF5_SPI2;
  HAL_GPIO_Init(GPIOI, &GPIO_InitStruct);

  /*Configure GPIO pins : EXP_GPIO3_Pin EXP_GPIO1_Pin */
  GPIO_InitStruct.Pin = EXP_GPIO3_Pin|EXP_GPIO1_Pin;
  GPIO_InitStruct.Mode = GPIO_MODE_OUTPUT_PP;
  GPIO_InitStruct.Pull = GPIO_NOPULL;
  GPIO_InitStruct.Speed = GPIO_SPEED_FREQ_LOW;
  HAL_GPIO_Init(GPIOC, &GPIO_InitStruct);

  /*Configure GPIO pins : FMC_A0_Pin FMC_A1_Pin FMC_A2_Pin FMC_A3_Pin
                           FMC_A4_Pin FMC_A5_Pin FMC_A6_Pin FMC_A9_Pin
                           FMC_A7_Pin FMC_A8_Pin FMC_SDNRAS_Pin */
  GPIO_InitStruct.Pin = FMC_A0_Pin|FMC_A1_Pin|FMC_A2_Pin|FMC_A3_Pin
                          |FMC_A4_Pin|FMC_A5_Pin|FMC_A6_Pin|FMC_A9_Pin
                          |FMC_A7_Pin|FMC_A8_Pin|FMC_SDNRAS_Pin;
  GPIO_InitStruct.Mode = GPIO_MODE_AF_PP;
  GPIO_InitStruct.Pull = GPIO_NOPULL;
  GPIO_InitStruct.Speed = GPIO_SPEED_FREQ_VERY_HIGH;
  GPIO_InitStruct.Alternate = GPIO_AF12_FMC;
  HAL_GPIO_Init(GPIOF, &GPIO_InitStruct);

  /*Configure GPIO pins : LTDC_HSYNC_Pin LTDC_G6_Pin LTDC_G5_Pin LTDC_VSYNC_Pin
                           LTDC_R0_Pin LTDC_CLK_Pin */
  GPIO_InitStruct.Pin = LTDC_HSYNC_Pin|LTDC_G6_Pin|LTDC_G5_Pin|LTDC_VSYNC_Pin
                          |LTDC_R0_Pin|LTDC_CLK_Pin;
  GPIO_InitStruct.Mode = GPIO_MODE_AF_PP;
  GPIO_InitStruct.Pull = GPIO_NOPULL;
  GPIO_InitStruct.Speed = GPIO_SPEED_FREQ_VERY_HIGH;
  GPIO_InitStruct.Alternate = GPIO_AF14_LTDC;
  HAL_GPIO_Init(GPIOI, &GPIO_InitStruct);

  /*Configure GPIO pin : WiFi_IRQ_Pin */
  GPIO_InitStruct.Pin = WiFi_IRQ_Pin;
  GPIO_InitStruct.Mode = GPIO_MODE_IT_RISING;
  GPIO_InitStruct.Pull = GPIO_NOPULL;
  HAL_GPIO_Init(WiFi_IRQ_GPIO_Port, &GPIO_InitStruct);

  /*Configure GPIO pin : SD_CMD_Pin */
  GPIO_InitStruct.Pin = SD_CMD_Pin;
  GPIO_InitStruct.Mode = GPIO_MODE_AF_PP;
  GPIO_InitStruct.Pull = GPIO_NOPULL;
  GPIO_InitStruct.Speed = GPIO_SPEED_FREQ_VERY_HIGH;
  GPIO_InitStruct.Alternate = GPIO_AF12_SDMMC1;
  HAL_GPIO_Init(SD_CMD_GPIO_Port, &GPIO_InitStruct);

  /*Configure GPIO pins : LTDC_G4_Pin LTDC_G2_Pin LTDC_R3_Pin */
  GPIO_InitStruct.Pin = LTDC_G4_Pin|LTDC_G2_Pin|LTDC_R3_Pin;
  GPIO_InitStruct.Mode = GPIO_MODE_AF_PP;
  GPIO_InitStruct.Pull = GPIO_NOPULL;
  GPIO_InitStruct.Speed = GPIO_SPEED_FREQ_VERY_HIGH;
  GPIO_InitStruct.Alternate = GPIO_AF14_LTDC;
  HAL_GPIO_Init(GPIOH, &GPIO_InitStruct);

  /*Configure GPIO pin : CAN_RX_Pin */
  GPIO_InitStruct.Pin = CAN_RX_Pin;
  GPIO_InitStruct.Mode = GPIO_MODE_AF_PP;
  GPIO_InitStruct.Pull = GPIO_NOPULL;
  GPIO_InitStruct.Speed = GPIO_SPEED_FREQ_VERY_HIGH;
  GPIO_InitStruct.Alternate = GPIO_AF9_CAN1;
  HAL_GPIO_Init(CAN_RX_GPIO_Port, &GPIO_InitStruct);

  /*Configure GPIO pins : DCMI_D4_Pin DCMI_D3_Pin DCMI_D1_Pin */
  GPIO_InitStruct.Pin = DCMI_D4_Pin|DCMI_D3_Pin|DCMI_D1_Pin;
  GPIO_InitStruct.Mode = GPIO_MODE_AF_PP;
  GPIO_InitStruct.Pull = GPIO_NOPULL;
  GPIO_InitStruct.Speed = GPIO_SPEED_FREQ_VERY_HIGH;
  GPIO_InitStruct.Alternate = GPIO_AF13_DCMI;
  HAL_GPIO_Init(GPIOH, &GPIO_InitStruct);

  /*Configure GPIO pin : VBATT_CHSTAT_Pin */
  GPIO_InitStruct.Pin = VBATT_CHSTAT_Pin;
  GPIO_InitStruct.Mode = GPIO_MODE_INPUT;
  GPIO_InitStruct.Pull = GPIO_NOPULL;
  HAL_GPIO_Init(VBATT_CHSTAT_GPIO_Port, &GPIO_InitStruct);

  /*Configure GPIO pins : LTDC_TPRST_Pin GSM_DTR_Pin */
  GPIO_InitStruct.Pin = LTDC_TPRST_Pin|GSM_DTR_Pin;
  GPIO_InitStruct.Mode = GPIO_MODE_OUTPUT_PP;
  GPIO_InitStruct.Pull = GPIO_NOPULL;
  GPIO_InitStruct.Speed = GPIO_SPEED_FREQ_LOW;
  HAL_GPIO_Init(GPIOK, &GPIO_InitStruct);

  /*Configure GPIO pin : PC9 */
  GPIO_InitStruct.Pin = GPIO_PIN_9;
  GPIO_InitStruct.Mode = GPIO_MODE_AF_PP;
  GPIO_InitStruct.Pull = GPIO_NOPULL;
  GPIO_InitStruct.Speed = GPIO_SPEED_FREQ_LOW;
  GPIO_InitStruct.Alternate = GPIO_AF0_MCO;
  HAL_GPIO_Init(GPIOC, &GPIO_InitStruct);

  /*Configure GPIO pin : PA8 */
  GPIO_InitStruct.Pin = GPIO_PIN_8;
  GPIO_InitStruct.Mode = GPIO_MODE_AF_OD;
  GPIO_InitStruct.Pull = GPIO_PULLUP;
  GPIO_InitStruct.Speed = GPIO_SPEED_FREQ_VERY_HIGH;
  GPIO_InitStruct.Alternate = GPIO_AF4_I2C3;
  HAL_GPIO_Init(GPIOA, &GPIO_InitStruct);

  /*Configure GPIO pins : LTDC_TPIRQ_Pin GSM_RI_Pin */
  GPIO_InitStruct.Pin = LTDC_TPIRQ_Pin|GSM_RI_Pin;
  GPIO_InitStruct.Mode = GPIO_MODE_INPUT;
  GPIO_InitStruct.Pull = GPIO_NOPULL;
  HAL_GPIO_Init(GPIOJ, &GPIO_InitStruct);

  /*Configure GPIO pin : GSM_RX_Pin */
  GPIO_InitStruct.Pin = GSM_RX_Pin;
  GPIO_InitStruct.Mode = GPIO_MODE_AF_PP;
  GPIO_InitStruct.Pull = GPIO_NOPULL;
  GPIO_InitStruct.Speed = GPIO_SPEED_FREQ_VERY_HIGH;
  GPIO_InitStruct.Alternate = GPIO_AF8_USART6;
  HAL_GPIO_Init(GSM_RX_GPIO_Port, &GPIO_InitStruct);

  /*Configure GPIO pins : LTDC_SCL_Pin LTDC_SDA_Pin */
  GPIO_InitStruct.Pin = LTDC_SCL_Pin|LTDC_SDA_Pin;
  GPIO_InitStruct.Mode = GPIO_MODE_AF_OD;
  GPIO_InitStruct.Pull = GPIO_PULLUP;
  GPIO_InitStruct.Speed = GPIO_SPEED_FREQ_VERY_HIGH;
  GPIO_InitStruct.Alternate = GPIO_AF4_I2C2;
  HAL_GPIO_Init(GPIOH, &GPIO_InitStruct);

  /*Configure GPIO pin : DCMI_D0_Pin */
  GPIO_InitStruct.Pin = DCMI_D0_Pin;
  GPIO_InitStruct.Mode = GPIO_MODE_AF_PP;
  GPIO_InitStruct.Pull = GPIO_NOPULL;
  GPIO_InitStruct.Speed = GPIO_SPEED_FREQ_VERY_HIGH;
  GPIO_InitStruct.Alternate = GPIO_AF13_DCMI;
  HAL_GPIO_Init(DCMI_D0_GPIO_Port, &GPIO_InitStruct);

  /*Configure GPIO pins : FMC_SDNE0_Pin FMC_SDCKE0_Pin */
  GPIO_InitStruct.Pin = FMC_SDNE0_Pin|FMC_SDCKE0_Pin;
  GPIO_InitStruct.Mode = GPIO_MODE_AF_PP;
  GPIO_InitStruct.Pull = GPIO_NOPULL;
  GPIO_InitStruct.Speed = GPIO_SPEED_FREQ_VERY_HIGH;
  GPIO_InitStruct.Alternate = GPIO_AF12_FMC;
  HAL_GPIO_Init(GPIOH, &GPIO_InitStruct);

  /*Configure GPIO pin : GSM_DCD_Pin */
  GPIO_InitStruct.Pin = GSM_DCD_Pin;
  GPIO_InitStruct.Mode = GPIO_MODE_OUTPUT_PP;
  GPIO_InitStruct.Pull = GPIO_NOPULL;
  GPIO_InitStruct.Speed = GPIO_SPEED_FREQ_LOW;
  HAL_GPIO_Init(GSM_DCD_GPIO_Port, &GPIO_InitStruct);

  /*Configure GPIO pin : LTDC_R7_Pin */
  GPIO_InitStruct.Pin = LTDC_R7_Pin;
  GPIO_InitStruct.Mode = GPIO_MODE_AF_PP;
  GPIO_InitStruct.Pull = GPIO_NOPULL;
  GPIO_InitStruct.Speed = GPIO_SPEED_FREQ_VERY_HIGH;
  GPIO_InitStruct.Alternate = GPIO_AF14_LTDC;
  HAL_GPIO_Init(LTDC_R7_GPIO_Port, &GPIO_InitStruct);

  /*Configure GPIO pin : LTDC_BL_Pin */
  GPIO_InitStruct.Pin = LTDC_BL_Pin;
  GPIO_InitStruct.Mode = GPIO_MODE_AF_PP;
  GPIO_InitStruct.Pull = GPIO_NOPULL;
  GPIO_InitStruct.Speed = GPIO_SPEED_FREQ_LOW;
  GPIO_InitStruct.Alternate = GPIO_AF3_TIM11;
  HAL_GPIO_Init(LTDC_BL_GPIO_Port, &GPIO_InitStruct);

  /*Configure GPIO pin : QSP_IO3_Pin */
  GPIO_InitStruct.Pin = QSP_IO3_Pin;
  GPIO_InitStruct.Mode = GPIO_MODE_AF_PP;
  GPIO_InitStruct.Pull = GPIO_NOPULL;
  GPIO_InitStruct.Speed = GPIO_SPEED_FREQ_VERY_HIGH;
  GPIO_InitStruct.Alternate = GPIO_AF9_QUADSPI;
  HAL_GPIO_Init(QSP_IO3_GPIO_Port, &GPIO_InitStruct);

  /*Configure GPIO pins : GSM_RST_Pin EXP_GPIO2_Pin */
  GPIO_InitStruct.Pin = GSM_RST_Pin|EXP_GPIO2_Pin;
  GPIO_InitStruct.Mode = GPIO_MODE_OUTPUT_PP;
  GPIO_InitStruct.Pull = GPIO_NOPULL;
  GPIO_InitStruct.Speed = GPIO_SPEED_FREQ_LOW;
  HAL_GPIO_Init(GPIOJ, &GPIO_InitStruct);

  /*Configure GPIO pin : EXP_GPIO0_Pin */
  GPIO_InitStruct.Pin = EXP_GPIO0_Pin;
  GPIO_InitStruct.Mode = GPIO_MODE_OUTPUT_PP;
  GPIO_InitStruct.Pull = GPIO_NOPULL;
  GPIO_InitStruct.Speed = GPIO_SPEED_FREQ_LOW;
  HAL_GPIO_Init(EXP_GPIO0_GPIO_Port, &GPIO_InitStruct);

  /*Configure GPIO pins : QSP_IO1_Pin QSP_IO0_Pin */
  GPIO_InitStruct.Pin = QSP_IO1_Pin|QSP_IO0_Pin;
  GPIO_InitStruct.Mode = GPIO_MODE_AF_PP;
  GPIO_InitStruct.Pull = GPIO_NOPULL;
  GPIO_InitStruct.Speed = GPIO_SPEED_FREQ_VERY_HIGH;
  GPIO_InitStruct.Alternate = GPIO_AF10_QUADSPI;
  HAL_GPIO_Init(GPIOF, &GPIO_InitStruct);

  /*Configure GPIO pin : FMC_SDNWE_Pin */
  GPIO_InitStruct.Pin = FMC_SDNWE_Pin;
  GPIO_InitStruct.Mode = GPIO_MODE_AF_PP;
  GPIO_InitStruct.Pull = GPIO_NOPULL;
  GPIO_InitStruct.Speed = GPIO_SPEED_FREQ_VERY_HIGH;
  GPIO_InitStruct.Alternate = GPIO_AF12_FMC;
  HAL_GPIO_Init(FMC_SDNWE_GPIO_Port, &GPIO_InitStruct);

  /*Configure GPIO pin : RMII_RXER_Pin */
  GPIO_InitStruct.Pin = RMII_RXER_Pin;
  GPIO_InitStruct.Mode = GPIO_MODE_INPUT;
  GPIO_InitStruct.Pull = GPIO_NOPULL;
  HAL_GPIO_Init(RMII_RXER_GPIO_Port, &GPIO_InitStruct);

  /*Configure GPIO pin : QSP_CLK_Pin */
  GPIO_InitStruct.Pin = QSP_CLK_Pin;
  GPIO_InitStruct.Mode = GPIO_MODE_AF_PP;
  GPIO_InitStruct.Pull = GPIO_NOPULL;
  GPIO_InitStruct.Speed = GPIO_SPEED_FREQ_VERY_HIGH;
  GPIO_InitStruct.Alternate = GPIO_AF9_QUADSPI;
  HAL_GPIO_Init(QSP_CLK_GPIO_Port, &GPIO_InitStruct);

  /*Configure GPIO pins : DCMI_HSYNC_Pin DCMI_PIXCLK_Pin */
  GPIO_InitStruct.Pin = DCMI_HSYNC_Pin|DCMI_PIXCLK_Pin;
  GPIO_InitStruct.Mode = GPIO_MODE_AF_PP;
  GPIO_InitStruct.Pull = GPIO_NOPULL;
  GPIO_InitStruct.Speed = GPIO_SPEED_FREQ_VERY_HIGH;
  GPIO_InitStruct.Alternate = GPIO_AF13_DCMI;
  HAL_GPIO_Init(GPIOA, &GPIO_InitStruct);

  /*Configure GPIO pin : SD_DETECT_Pin */
  GPIO_InitStruct.Pin = SD_DETECT_Pin;
  GPIO_InitStruct.Mode = GPIO_MODE_INPUT;
  GPIO_InitStruct.Pull = GPIO_NOPULL;
  HAL_GPIO_Init(SD_DETECT_GPIO_Port, &GPIO_InitStruct);

  /*Configure GPIO pins : GSM_PWE_Pin EXP_GPIO4_Pin */
  GPIO_InitStruct.Pin = GSM_PWE_Pin|EXP_GPIO4_Pin;
  GPIO_InitStruct.Mode = GPIO_MODE_OUTPUT_PP;
  GPIO_InitStruct.Pull = GPIO_NOPULL;
  GPIO_InitStruct.Speed = GPIO_SPEED_FREQ_LOW;
  HAL_GPIO_Init(GPIOH, &GPIO_InitStruct);

  /*Configure GPIO pin : DCMI_SCLA5_Pin */
  GPIO_InitStruct.Pin = DCMI_SCLA5_Pin;
  GPIO_InitStruct.Mode = GPIO_MODE_AF_PP;
  GPIO_InitStruct.Pull = GPIO_NOPULL;
  GPIO_InitStruct.Speed = GPIO_SPEED_FREQ_VERY_HIGH;
  GPIO_InitStruct.Alternate = GPIO_AF5_SPI1;
  HAL_GPIO_Init(DCMI_SCLA5_GPIO_Port, &GPIO_InitStruct);

  /*Configure GPIO pins : RS485_TX_Pin RS485_RX_Pin */
  GPIO_InitStruct.Pin = RS485_TX_Pin|RS485_RX_Pin;
  GPIO_InitStruct.Mode = GPIO_MODE_AF_PP;
  GPIO_InitStruct.Pull = GPIO_NOPULL;
  GPIO_InitStruct.Speed = GPIO_SPEED_FREQ_VERY_HIGH;
  GPIO_InitStruct.Alternate = GPIO_AF7_USART3;
  HAL_GPIO_Init(GPIOB, &GPIO_InitStruct);

  /*Configure GPIO pin : EXP_SDA_Pin */
  GPIO_InitStruct.Pin = EXP_SDA_Pin;
  GPIO_InitStruct.Mode = GPIO_MODE_AF_OD;
  GPIO_InitStruct.Pull = GPIO_PULLUP;
  GPIO_InitStruct.Speed = GPIO_SPEED_FREQ_VERY_HIGH;
  GPIO_InitStruct.Alternate = GPIO_AF4_I2C3;
  HAL_GPIO_Init(EXP_SDA_GPIO_Port, &GPIO_InitStruct);

  /*Configure GPIO pin : RS485_DE_Pin */
  GPIO_InitStruct.Pin = RS485_DE_Pin;
  GPIO_InitStruct.Mode = GPIO_MODE_OUTPUT_PP;
  GPIO_InitStruct.Pull = GPIO_NOPULL;
  GPIO_InitStruct.Speed = GPIO_SPEED_FREQ_LOW;
  HAL_GPIO_Init(RS485_DE_GPIO_Port, &GPIO_InitStruct);

  /*Configure GPIO pin : DCMI_LIGHT_Pin */
  GPIO_InitStruct.Pin = DCMI_LIGHT_Pin;
  GPIO_InitStruct.Mode = GPIO_MODE_AF_PP;
  GPIO_InitStruct.Pull = GPIO_NOPULL;
  GPIO_InitStruct.Speed = GPIO_SPEED_FREQ_LOW;
  GPIO_InitStruct.Alternate = GPIO_AF3_TIM8;
  HAL_GPIO_Init(DCMI_LIGHT_GPIO_Port, &GPIO_InitStruct);

  /*Configure GPIO pins : USB_DM_Pin USB_DP_Pin */
  GPIO_InitStruct.Pin = USB_DM_Pin|USB_DP_Pin;
  GPIO_InitStruct.Mode = GPIO_MODE_AF_PP;
  GPIO_InitStruct.Pull = GPIO_NOPULL;
  GPIO_InitStruct.Speed = GPIO_SPEED_FREQ_VERY_HIGH;
  GPIO_InitStruct.Alternate = GPIO_AF12_OTG_HS_FS;
  HAL_GPIO_Init(GPIOB, &GPIO_InitStruct);

}

void StartDefaultTask(void const * argument)
{
  /* init code for LWIP */
  MX_LWIP_Init();

  http_server_netconn_init();

  for(;;)
  {
    osDelay(1);
  }
}

void HAL_TIM_PeriodElapsedCallback(TIM_HandleTypeDef *htim)
{
  if (htim->Instance == TIM1) {
    HAL_IncTick();
  }
}

void Error_Handler(void)
{
}

/************************ (C) COPYRIGHT STMicroelectronics *****END OF FILE****/
